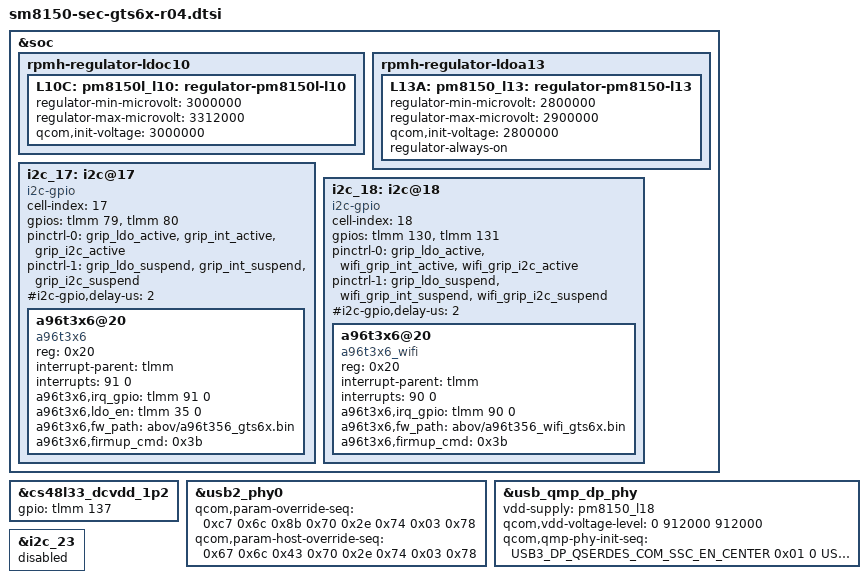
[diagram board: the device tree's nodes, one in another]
/* Copyright (c) 2016-2017, The Linux Foundation. All rights reserved.
 *
 * This program is free software; you can redistribute it and/or modify
 * it under the terms of the GNU General Public License version 2 and
 * only version 2 as published by the Free Software Foundation.
 *
 * This program is distributed in the hope that it will be useful,
 * but WITHOUT ANY WARRANTY; without even the implied warranty of
 * MERCHANTABILITY or FITNESS FOR A PARTICULAR PURPOSE.  See the
 * GNU General Public License for more details.
 */

#include "sm8150-sec-gts6x-common.dtsi"

&soc {
	/* for WIFI */
	rpmh-regulator-ldoc10 {
		L10C: pm8150l_l10: regulator-pm8150l-l10 {
			regulator-min-microvolt = <3000000>;
			regulator-max-microvolt = <3312000>;
			qcom,init-voltage = <3000000>;
		};
	};

	/* RGB Sensor */
	rpmh-regulator-ldoa13 {
		L13A: pm8150_l13: regulator-pm8150-l13 {
			regulator-min-microvolt = <2800000>;
			regulator-max-microvolt = <2900000>;
			qcom,init-voltage = <2800000>;
			regulator-always-on;
		};
	};
	
	i2c_17: i2c@17 { /* SW I2C */
		status = "ok";

		cell-index = <17>;
		compatible = "i2c-gpio";
		gpios = <&tlmm 79 0 /* sda */
			 &tlmm 80 0 /* scl */
		>;
		pinctrl-names = "default", "sleep";
		pinctrl-0 = <&grip_ldo_active &grip_int_active &grip_i2c_active>;
		pinctrl-1 = <&grip_ldo_suspend &grip_int_suspend &grip_i2c_suspend>;

		#i2c-gpio,delay-us = <2>;
		#address-cells = <1>;
		#size-cells = <0>;
		a96t3x6@20 {
			compatible = "a96t3x6";
			reg = <0x20>;

			interrupt-parent = <&tlmm>;
			interrupts = <91 0>;

			a96t3x6,irq_gpio = <&tlmm 91 0>;
			a96t3x6,ldo_en = <&tlmm 35 0>;
			a96t3x6,fw_path = "abov/a96t356_gts6x.bin";
			a96t3x6,firmup_cmd = <0x3b>;
		};
	};
	
	i2c_18: i2c@18 { /* SW I2C */
		status = "ok";

		cell-index = <18>;
		compatible = "i2c-gpio";
		gpios = <&tlmm 130 0 /* sda */
			 &tlmm 131 0 /* scl */
		>;
		pinctrl-names = "default", "sleep";
		pinctrl-0 = <&grip_ldo_active &wifi_grip_int_active &wifi_grip_i2c_active>;
		pinctrl-1 = <&grip_ldo_suspend &wifi_grip_int_suspend &wifi_grip_i2c_suspend>;

		#i2c-gpio,delay-us = <2>;
		#address-cells = <1>;
		#size-cells = <0>;
		a96t3x6@20 {
			compatible = "a96t3x6_wifi";
			reg = <0x20>;

			interrupt-parent = <&tlmm>;
			interrupts = <90 0>;

			a96t3x6,irq_gpio = <&tlmm 90 0>;
			a96t3x6,fw_path = "abov/a96t356_wifi_gts6x.bin";
			a96t3x6,firmup_cmd = <0x3b>;
		};
	};	
};

&cs48l33_dcvdd_1p2 {
	gpio = <&tlmm 137 0>; /* VOICE_LDO_ENABLE */
};

&usb2_phy0 {
	qcom,param-override-seq =
		<0xc7 0x6c
		 0x8b 0x70
		 0x2e 0x74
		 0x03 0x78>;
	qcom,param-host-override-seq =
		<0x67 0x6c
		 0x43 0x70
		 0x2e 0x74
		 0x03 0x78>;
};

&usb_qmp_dp_phy {
	vdd-supply = <&pm8150_l18>;
	qcom,vdd-voltage-level = <0 912000 912000>;
	qcom,qmp-phy-init-seq =
	    <USB3_DP_QSERDES_COM_SSC_EN_CENTER 0x01 0
	     USB3_DP_QSERDES_COM_SSC_PER1 0x31 0
	     USB3_DP_QSERDES_COM_SSC_PER2 0x01 0
	     USB3_DP_QSERDES_COM_SSC_STEP_SIZE1_MODE0 0xde 0
	     USB3_DP_QSERDES_COM_SSC_STEP_SIZE2_MODE0 0x07 0
	     USB3_DP_QSERDES_COM_SSC_STEP_SIZE1_MODE1 0xde 0
	     USB3_DP_QSERDES_COM_SSC_STEP_SIZE2_MODE1 0x07 0
	     USB3_DP_QSERDES_COM_SYSCLK_BUF_ENABLE 0x0a 0
	     USB3_DP_QSERDES_COM_CP_CTRL_MODE0 0x06 0
	     USB3_DP_QSERDES_COM_CP_CTRL_MODE1 0x06 0
	     USB3_DP_QSERDES_COM_PLL_RCTRL_MODE0 0x16 0
	     USB3_DP_QSERDES_COM_PLL_RCTRL_MODE1 0x16 0
	     USB3_DP_QSERDES_COM_PLL_CCTRL_MODE0 0x36 0
	     USB3_DP_QSERDES_COM_PLL_CCTRL_MODE1 0x36 0
	     USB3_DP_QSERDES_COM_SYSCLK_EN_SEL 0x1a 0
	     USB3_DP_QSERDES_COM_LOCK_CMP_EN 0x04 0
	     USB3_DP_QSERDES_COM_LOCK_CMP1_MODE0 0x14 0
	     USB3_DP_QSERDES_COM_LOCK_CMP2_MODE0 0x34 0
	     USB3_DP_QSERDES_COM_LOCK_CMP1_MODE1 0x34 0
	     USB3_DP_QSERDES_COM_LOCK_CMP2_MODE1 0x82 0
	     USB3_DP_QSERDES_COM_DEC_START_MODE0 0x82 0
	     USB3_DP_QSERDES_COM_DEC_START_MODE1 0x82 0
	     USB3_DP_QSERDES_COM_DIV_FRAC_START1_MODE0 0xab 0
	     USB3_DP_QSERDES_COM_DIV_FRAC_START2_MODE0 0xea 0
	     USB3_DP_QSERDES_COM_DIV_FRAC_START3_MODE0 0x02 0
	     USB3_DP_QSERDES_COM_DIV_FRAC_START1_MODE1 0xab 0
	     USB3_DP_QSERDES_COM_DIV_FRAC_START2_MODE1 0xea 0
	     USB3_DP_QSERDES_COM_DIV_FRAC_START3_MODE1 0x02 0
	     USB3_DP_QSERDES_COM_VCO_TUNE1_MODE0 0x24 0
	     USB3_DP_QSERDES_COM_VCO_TUNE1_MODE1 0x24 0
	     USB3_DP_QSERDES_COM_VCO_TUNE2_MODE1 0x02 0
	     USB3_DP_QSERDES_COM_HSCLK_SEL 0x01 0
	     USB3_DP_QSERDES_COM_CORECLK_DIV_MODE1 0x08 0
	     USB3_DP_QSERDES_COM_SVS_MODE_CLK_SEL 0x2 0
	     USB3_DP_QSERDES_COM_BIN_VCOCAL_CMP_CODE1_MODE0 0xca 0
	     USB3_DP_QSERDES_COM_BIN_VCOCAL_CMP_CODE2_MODE0 0x1e 0
	     USB3_DP_QSERDES_COM_BIN_VCOCAL_CMP_CODE1_MODE1 0xca 0
	     USB3_DP_QSERDES_COM_BIN_VCOCAL_CMP_CODE2_MODE1 0x1e 0
	     USB3_DP_QSERDES_COM_BIN_VCOCAL_HSCLK_SEL 0x11 0
	     USB3_DP_QSERDES_COM_VCO_TUNE_MAP 0x02 0
	     USB3_DP_QSERDES_COM_CMN_IPTRIM 0x20 0
	     USB3_DP_QSERDES_TXA_LANE_MODE_1 0xd5 0
	     USB3_DP_QSERDES_TXA_RCV_DETECT_LVL_2 0x12 0
	     USB3_DP_QSERDES_TXA_RES_CODE_LANE_TX 0x00 0
	     USB3_DP_QSERDES_TXA_RES_CODE_LANE_RX 0x00 0
	     USB3_DP_QSERDES_TXA_RES_CODE_LANE_OFFSET_TX 0x16 0
	     USB3_DP_QSERDES_TXA_RES_CODE_LANE_OFFSET_RX 0x05 0
	     USB3_DP_QSERDES_TXA_PI_QEC_CTRL 0x20 0
	     USB3_DP_QSERDES_RXA_UCDR_SO_GAIN 0x04 0
	     USB3_DP_QSERDES_RXA_UCDR_FASTLOCK_FO_GAIN 0x2f 0
	     USB3_DP_QSERDES_RXA_UCDR_SO_SATURATION_AND_ENABLE 0x7f 0
	     USB3_DP_QSERDES_RXA_UCDR_FASTLOCK_COUNT_LOW 0xff 0
	     USB3_DP_QSERDES_RXA_UCDR_FASTLOCK_COUNT_HIGH 0x0f 0
	     USB3_DP_QSERDES_RXA_UCDR_PI_CONTROLS 0x99 0
	     USB3_DP_QSERDES_RXA_UCDR_SB2_THRESH1 0x04 0
	     USB3_DP_QSERDES_RXA_UCDR_SB2_THRESH2 0x08 0
	     USB3_DP_QSERDES_RXA_UCDR_SB2_GAIN1 0x05 0
	     USB3_DP_QSERDES_RXA_UCDR_SB2_GAIN2 0x05 0
	     USB3_DP_QSERDES_RXA_AUX_DATA_TCOARSE_TFINE 0xa0 0
	     USB3_DP_QSERDES_RXA_VGA_CAL_CNTRL1 0x54 0
	     USB3_DP_QSERDES_RXA_VGA_CAL_CNTRL2 0x0e 0
	     USB3_DP_QSERDES_RXA_GM_CAL 0x1f 0
	     USB3_DP_QSERDES_RXA_RX_EQU_ADAPTOR_CNTRL2 0x0f 0
	     USB3_DP_QSERDES_RXA_RX_EQU_ADAPTOR_CNTRL3 0x4a 0
	     USB3_DP_QSERDES_RXA_RX_EQU_ADAPTOR_CNTRL4 0x0a 0
	     USB3_DP_QSERDES_RXA_RX_IDAC_TSETTLE_LOW 0xc0 0
	     USB3_DP_QSERDES_RXA_RX_IDAC_TSETTLE_HIGH 0x00 0
	     USB3_DP_QSERDES_RXA_RX_EQ_OFFSET_ADAPTOR_CNTRL1 0x77 0
	     USB3_DP_QSERDES_RXA_RX_OFFSET_ADAPTOR_CNTRL2 0x80 0
	     USB3_DP_QSERDES_RXA_SIGDET_CNTRL 0x04 0
	     USB3_DP_QSERDES_RXA_SIGDET_DEGLITCH_CNTRL 0x0e 0
	     USB3_DP_QSERDES_RXA_RX_MODE_00_LOW 0xbf 0
	     USB3_DP_QSERDES_RXA_RX_MODE_00_HIGH 0xbf 0
	     USB3_DP_QSERDES_RXA_RX_MODE_00_HIGH2 0x3f 0
	     USB3_DP_QSERDES_RXA_RX_MODE_00_HIGH3 0x7f 0
	     USB3_DP_QSERDES_RXA_RX_MODE_00_HIGH4 0x94 0
	     USB3_DP_QSERDES_RXA_RX_MODE_01_LOW 0xdc 0
	     USB3_DP_QSERDES_RXA_RX_MODE_01_HIGH 0xdc 0
	     USB3_DP_QSERDES_RXA_RX_MODE_01_HIGH2 0x5c 0
	     USB3_DP_QSERDES_RXA_RX_MODE_01_HIGH3 0x0b 0
	     USB3_DP_QSERDES_RXA_RX_MODE_01_HIGH4 0xbf 0
	     USB3_DP_QSERDES_RXA_DFE_EN_TIMER 0x04 0
	     USB3_DP_QSERDES_RXA_DFE_CTLE_POST_CAL_OFFSET 0x38 0
	     USB3_DP_QSERDES_RXA_DCC_CTRL1 0xc 0
	     USB3_DP_QSERDES_RXA_VTH_CODE 0x10 0
	     USB3_DP_QSERDES_TXB_LANE_MODE_1 0xd5 0
	     USB3_DP_QSERDES_TXB_RCV_DETECT_LVL_2 0x12 0
	     USB3_DP_QSERDES_TXB_RES_CODE_LANE_TX 0x00 0
	     USB3_DP_QSERDES_TXB_RES_CODE_LANE_RX 0x00 0
	     USB3_DP_QSERDES_TXB_RES_CODE_LANE_OFFSET_TX 0x16 0
	     USB3_DP_QSERDES_TXB_RES_CODE_LANE_OFFSET_RX 0x05 0
	     USB3_DP_QSERDES_TXB_PI_QEC_CTRL 0x20 0
	     USB3_DP_QSERDES_RXB_UCDR_SO_GAIN 0x04 0
	     USB3_DP_QSERDES_RXB_UCDR_FASTLOCK_FO_GAIN 0x2f 0
	     USB3_DP_QSERDES_RXB_UCDR_SO_SATURATION_AND_ENABLE 0x7f 0
	     USB3_DP_QSERDES_RXB_UCDR_FASTLOCK_COUNT_LOW 0xff 0
	     USB3_DP_QSERDES_RXB_UCDR_FASTLOCK_COUNT_HIGH 0x0f 0
	     USB3_DP_QSERDES_RXB_UCDR_PI_CONTROLS 0x99 0
	     USB3_DP_QSERDES_RXB_UCDR_SB2_THRESH1 0x04 0
	     USB3_DP_QSERDES_RXB_UCDR_SB2_THRESH2 0x08 0
	     USB3_DP_QSERDES_RXB_UCDR_SB2_GAIN1 0x05 0
	     USB3_DP_QSERDES_RXB_UCDR_SB2_GAIN2 0x05 0
	     USB3_DP_QSERDES_RXB_AUX_DATA_TCOARSE_TFINE 0xa0 0
	     USB3_DP_QSERDES_RXB_VGA_CAL_CNTRL1 0x54 0
	     USB3_DP_QSERDES_RXB_VGA_CAL_CNTRL2 0x0e 0
	     USB3_DP_QSERDES_RXB_GM_CAL 0x1f 0
	     USB3_DP_QSERDES_RXB_RX_EQU_ADAPTOR_CNTRL2 0x0f 0
	     USB3_DP_QSERDES_RXB_RX_EQU_ADAPTOR_CNTRL3 0x4a 0
	     USB3_DP_QSERDES_RXB_RX_EQU_ADAPTOR_CNTRL4 0x0a 0
	     USB3_DP_QSERDES_RXB_RX_IDAC_TSETTLE_LOW 0xc0 0
	     USB3_DP_QSERDES_RXB_RX_IDAC_TSETTLE_HIGH 0x00 0
	     USB3_DP_QSERDES_RXB_RX_EQ_OFFSET_ADAPTOR_CNTRL1 0x77 0
	     USB3_DP_QSERDES_RXB_RX_OFFSET_ADAPTOR_CNTRL2 0x80 0
	     USB3_DP_QSERDES_RXB_SIGDET_CNTRL 0x04 0
	     USB3_DP_QSERDES_RXB_SIGDET_DEGLITCH_CNTRL 0x0e 0
	     USB3_DP_QSERDES_RXB_RX_MODE_00_LOW 0xbf 0
	     USB3_DP_QSERDES_RXB_RX_MODE_00_HIGH 0xbf 0
	     USB3_DP_QSERDES_RXB_RX_MODE_00_HIGH2 0x3f 0
	     USB3_DP_QSERDES_RXB_RX_MODE_00_HIGH3 0x7f 0
	     USB3_DP_QSERDES_RXB_RX_MODE_00_HIGH4 0x94 0
	     USB3_DP_QSERDES_RXB_RX_MODE_01_LOW 0xdc 0
	     USB3_DP_QSERDES_RXB_RX_MODE_01_HIGH 0xdc 0
	     USB3_DP_QSERDES_RXB_RX_MODE_01_HIGH2 0x5c 0
	     USB3_DP_QSERDES_RXB_RX_MODE_01_HIGH3 0x0b 0
	     USB3_DP_QSERDES_RXB_RX_MODE_01_HIGH4 0xbf 0
	     USB3_DP_QSERDES_RXB_DFE_EN_TIMER 0x04 0
	     USB3_DP_QSERDES_RXB_DFE_CTLE_POST_CAL_OFFSET 0x38 0
	     USB3_DP_QSERDES_RXB_DCC_CTRL1 0xc 0
	     USB3_DP_QSERDES_RXB_VTH_CODE 0x10 0
	     USB3_DP_PCS_LOCK_DETECT_CONFIG1 0xd0 0
	     USB3_DP_PCS_LOCK_DETECT_CONFIG2 0x17 0
	     USB3_DP_PCS_LOCK_DETECT_CONFIG3 0x20 0
	     USB3_DP_PCS_RX_SIGDET_LVL 0xaa 0
	     USB3_DP_PCS_ALIGN_DETECT_CONFIG1 0x88 0
	     USB3_DP_PCS_ALIGN_DETECT_CONFIG2 0x13 0
	     USB3_DP_PCS_EQ_CONFIG1 0x0d 0
	     USB3_DP_PCS_EQ_CONFIG5 0x50 0
	     USB3_DP_PCS_USB3_LFPS_DET_HIGH_COUNT_VAL 0xf8 0
	     USB3_DP_PCS_USB3_RXEQTRAINING_DFE_TIME_S2 0x07 0
	     0xffffffff 0xffffffff 0x00>;
};

&i2c_23 {
	status = "disabled";
};

